# PY32M070Cxx register map
Vendor: Puya; Series: PY32M; File version: 1.0.0
Arm 32-bit Cortex-M0+ Microcontroller based device, CPU clock up to 48 MHz.
CPU: CM0+ r0p1, little endian, no MPU, no FPU, 4 interrupt priority bits
Registers are 32-bit, read-write, reset 0x0 unless marked. A register's access mark holds for its fields unless they carry their own. Offsets are from the block's base; lines under a group give offsets from that group; [hi:lo] are bit positions; {n}, {i} and the like mark numbered series; 'fields as' and 'values as' point back to an identical list; <NAME> marks a mode.

## Memory map
0x40000000 TIM2 size 0x400 — desc TIM
0x40000400 TIM3 size 0x400 — General purpose timer
0x40001000 TIM6 size 0x400 — desc TIM
0x40001400 TIM7 size 0x400 — desc TIM
0x40002000 TIM14 size 0x400 — General purpose timer
0x40002400 LCD size 0x400 — LCD CONTROLLER
0x40002800 RTC size 0x400
0x40002C00 WWDG size 0x400 — Window watchdog
0x40003000 IWDG size 0x400 — Independent watchdog
0x40003800 SPI2 size 0x400
0x40004400 USART2 size 0x400
0x40004800 USART3 size 0x400 — desc USART
0x40004C00 USART4 size 0x400 — desc USART
0x40005400 I2C1 size 0x400 — Inter integrated circuit
0x40005800 I2C2 size 0x400 — desc I2C
0x40005C00 USB size 0x400
0x40006400 CAN size 0x400
0x40006C00 CTC size 0x400
0x40007000 PWR size 0x400 — Power control
0x40007400 DAC size 0x400
0x40007C00 LPTIM1 size 0x400 — Low power timer
0x40010000 SYSCFG size 0x200
0x40010200 COMP1 size 0x10 — Comparator 1
0x40010210 COMP2 size 0x10 — Comparator2
0x40010220 COMP3 size 0x10 — Comparator3
0x40010300 OPA size 0x400 — des OPA
0x40012400 ADC size 0x400 — Analog to Digital Converter
0x40012C00 TIM1 size 0x400 — Advanced timer
0x40013000 SPI1 size 0x400 — Serial peripheral interface
0x40013800 USART1 size 0x400 — Universal synchronous asynchronous receiver transmitter
0x40014000 TIM15 size 0x400
0x40014400 TIM16 size 0x400 — General purpose timer
0x40014800 TIM17 size 0x400
0x40015800 DBGMCU size 0x400 — Debug support
0x40020000 DMA size 0x400 — Direct memory access
0x40021000 RCC size 0x400 — Reset and clock control
0x40021800 EXTI size 0x400 — External interrupt/event controller
0x40022000 FLASH size 0x400
0x40023000 CRC size 0x400 — CRC calculation unit
0x40023800 DIV size 0x400 — Hardware Divider
0x50000000 GPIOA size 0x400 — General-purpose I/Os
0x50000400 GPIOB size 0x400 — General-purpose I/Os
0x50000800 GPIOC size 0x400 — General-purpose I/Os
0x50001400 GPIOF size 0x400 — General-purpose I/Os

## Interrupts
0 WWDG — Window WatchDog Interrupt
1 PVD (EXTI) — PVD Interrupt through EXTI Lines 16
2 RTC — RTC Interrupt through EXTI Lines 19
3 FLASH — FLASH global Interrupt
4 RCC_CTC (CTC, RCC) — RCC and CTC global Interrupts
5 EXTI0_1 (EXTI) — EXTI Line 0 and 1 Interrupt
6 EXTI2_3 (EXTI) — EXTI Line 2 and 3 Interrupt
7 EXTI4_15 (EXTI) — EXTI Line 4 to 15 Interrupt
8 LCD — LCD global Interrupt
9 DMA1_Channel1 (DMA) — DMA1 Channel 1 Interrupt
10 DMA1_Channel2_3 (DMA) — DMA1 Channel 2 and Channel 3 Interrupt
11 DMA1_Channel4_5_6_7 (DMA) — DMA1 Channel 4, 5, 6, 7 Interrupts
12 ADC_COMP (ADC, COMP{n} (n=1..3)) — ADC and COMP Interrupt through EXTI Lines 17 and 18
13 TIM1_BRK_UP_TRG_COM (TIM1) — TIM1 Break, Update, Trigger and Commutation Interrupt
14 TIM1_CC (TIM1) — TIM1 Capture Compare Interrupt
15 TIM2 — TIM2 global Interrupt
16 TIM3 — TIM3 global Interrupt
17 TIM6_LPTIM1_DAC (DAC, LPTIM1, TIM6) — TIM6, LPTIM1, DAC global Interrupts
18 TIM7 — TIM7 global Interrupt
19 TIM14 — TIM14 global Interrupt
20 TIM15 — TIM15 global Interrupt
21 TIM16 — TIM16 global Interrupt
22 TIM17 — TIM17 global Interrupt
23 I2C1 — I2C1 global Interrupt
24 I2C2 — I2C2 Event Interrupt
25 SPI1 — SPI1 global Interrupt
26 SPI2 — SPI2 global Interrupt
27 USART1 — USART1 global Interrupt
28 USART2 — USART2 global Interrupt
29 USART3_4 (USART3, USART4) — USART3, 4 global Interrupts
30 CAN — CAN global Interrupt
31 USB — USB global Interrupts

## ADC — Analog to Digital Converter
Base 0x40012400
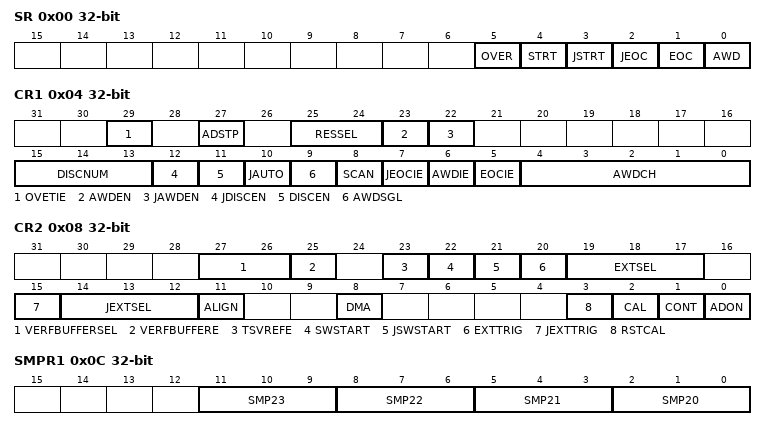
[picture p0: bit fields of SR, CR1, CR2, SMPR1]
0x00 SR
  [5] OVER ro, [4] STRT, [3] JSTRT, [2] JEOC, [1] EOC, [0] AWD
0x04 CR1
  [29] OVETIE
  [27] ADSTP
  [25:24] RESSEL
    1=0; 2=1
  [23] AWDEN
  [22] JAWDEN
  [15:13] DISCNUM
    1=0; 2=1; 4=2
  [12] JDISCEN
  [11] DISCEN
  [10] JAUTO
  [9] AWDSGL
  [8] SCAN
  [7] JEOCIE
  [6] AWDIE
  [5] EOCIE
  [4:0] AWDCH
    1=0; 2=1; 4=2; 8=3; 16=4
0x08 CR2
  [27:26] VERFBUFFERSEL
  [25] VERFBUFFERE
  [23] TSVREFE
  [22] SWSTART
  [21] JSWSTART
  [20] EXTTRIG
  [19:17] EXTSEL
    1=0; 2=1; 4=2
  [15] JEXTTRIG
  [14:12] JEXTSEL
    1=0; 2=1; 4=2
  [11] ALIGN
  [8] DMA
  [3] RSTCAL
  [2] CAL
  [1] CONT
  [0] ADON
0x0C SMPR1
  [all] fields
    1=0; 2=1; 4=2
  [3n-58:3n-60] SMP{n} (n=20..23)
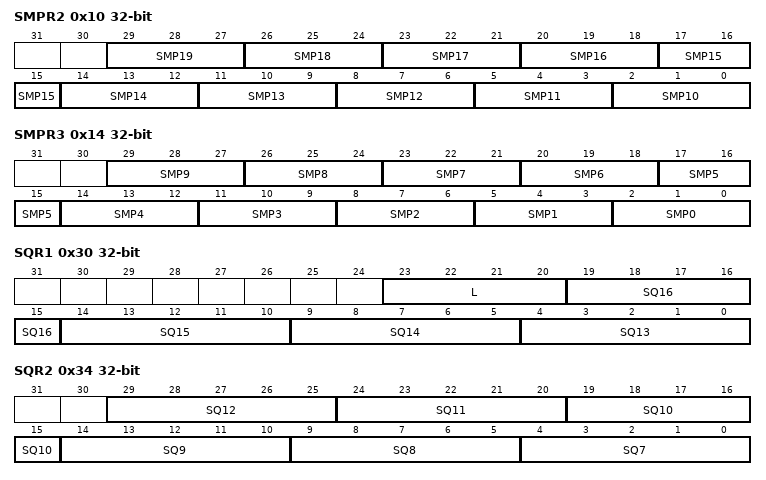
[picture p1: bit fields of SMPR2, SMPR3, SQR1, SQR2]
0x10 SMPR2
  [all] fields
    1=0; 2=1; 4=2
  [3n-28:3n-30] SMP{n} (n=10..19)
0x14 SMPR3 — desc SMPR2
  [all] fields
    1=0; 2=1; 4=2
  [3n+2:3n] SMP{n} (n=0..9)
{0x14+4i} JOFR{i} (i=1..4)
  [11:0] JOFFSET{i}
0x28 HTR
  [11:0] HT
0x2C LTR
  [11:0] LT
0x30 SQR1
  [23:20] L
    1=0; 2=1; 4=2; 8=3
  [5n-61:5n-65] SQ{n} (n=13..16)
    1=0; 2=1; 4=2; 8=3; 16=4
0x34 SQR2
  [all] fields
    1=0; 2=1; 4=2; 8=3; 16=4
  [5n-31:5n-35] SQ{n} (n=7..12)
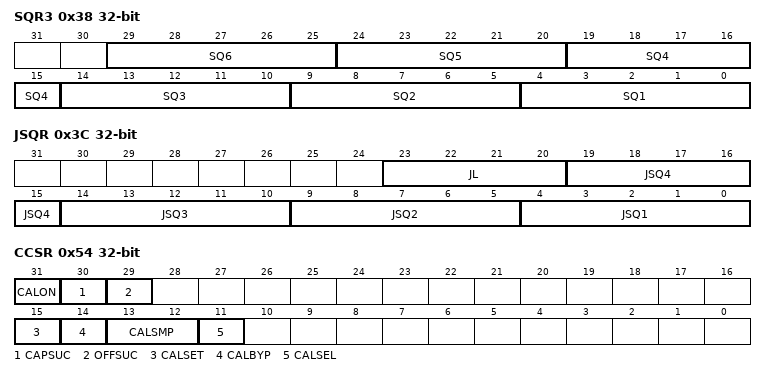
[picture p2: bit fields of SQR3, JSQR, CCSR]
0x38 SQR3
  [29:25] SQ6
    1=0; 2=1; 4=2; 8=3; 16=4
  [24:20] SQ5
  [5n-1:5n-5] SQ{n} (n=1..4)
    1=0; 2=1; 4=2; 8=3; 16=4
0x3C JSQR
  [23:20] JL
    1=0; 2=1; 4=2; 8=3
  [5n-1:5n-5] JSQ{n} (n=1..4)
    1=0; 2=1; 4=2; 8=3; 16=4
{0x3C+4i} JDR{i} ro (i=1..4)
  [15:0] JDR{i}
0x50 DR ro
  [15:0] DATA
0x54 CCSR
  [31] CALON ro
  [30] CAPSUC
  [29] OFFSUC
  [15] CALSET
  [14] CALBYP
  [13:12] CALSMP
    1=0; 2=1
  [11] CALSEL
